# STM32F378xx register map
File version: 1.0
Registers are 32-bit, read-write, reset 0x0 unless marked. A register's access mark holds for its fields unless they carry their own. Offsets are from the block's base; [hi:lo] are bit positions.

## COMP12_COMMON
Base 0x4001001C; alternate view of COMP
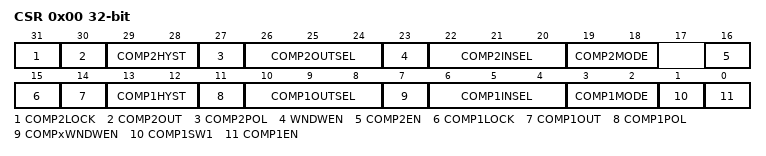
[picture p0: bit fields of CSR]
0x00 CSR — COMP control and status register, used for bits common to several COMP instances
  [31] COMP2LOCK
  [30] COMP2OUT — COMP2 output level
  [29:28] COMP2HYST — COMP2 hysteresis
  [27] COMP2POL — COMP2 output polarity
  [26:24] COMP2OUTSEL — COMP2 output select
  [23] WNDWEN — Comparators window mode enable
    0=DISABLE (Window mode disable: Comparators 1 and 2 are independent); 1=COMP1_INPUT_PLUS_COMMON (Window mode enable: Comparators instances pair COMP1 and COMP2 have their input plus connected together. The common input is COMP1 input plus (COMP2 input plus is no more accessible).)
  [22:20] COMP2INSEL — COMP2 inverting input select
  [19:18] COMP2MODE — COMP2 power mode
  [16] COMP2EN — COMP2 enable
  [15] COMP1LOCK
  [14] COMP1OUT — COMP1 output level
  [13:12] COMP1HYST — COMP1 hysteresis
    0=NONE (No hysteresis); 1=LOW (Hysteresis level low (available only on devices: STM32F303xB/C, STM32F358xC)); 2=MEDIUM (Hysteresis level medium (available only on devices: STM32F303xB/C, STM32F358xC)); 3=HIGH (Hysteresis level high (available only on devices: STM32F303xB/C, STM32F358xC))
  [11] COMP1POL — COMP1 output polarity
    0=NONINVERTED (COMP output polarity is not inverted: comparator output is high when the plus (non-inverting) input is at a higher voltage than the minus (inverting) input); 1=INVERTED (COMP output polarity is inverted: comparator output is low when the plus (non-inverting) input is at a lower voltage than the minus (inverting) input)
  [10:8] COMP1OUTSEL — COMP1 output select
    0=NONE (COMP output is not connected to other peripherals (except GPIO and EXTI that are always connected to COMP output) (specific to COMP instance: COMP2)); 1=TIM16_BKIN (COMP output connected to TIM16 break input (BKIN). Caution: Parameter specific to COMP instances, defined with generic naming, not taking into account COMP instance constraints. Refer to literal definitions above for COMP instance constraints.); 2=TIM4_IC1 (COMP output connected to TIM4 input capture 1. Caution: Parameter specific to COMP instances, defined with generic naming, not taking into account COMP instance constraints. Refer to literal definitions above for COMP instance constraints.); 3=TIM4_OCCLR (COMP output connected to TIM4 OCREF clear. Caution: Parameter specific to COMP instances, defined with generic naming, not taking into account COMP instance constraints. Refer to literal definitions above for COMP instance constraints.); 4=TIM2_IC4 (COMP output connected to TIM2 input capture 4. Caution: Parameter specific to COMP instances, defined with generic naming, not taking into account COMP instance constraints. Refer to literal definitions above for COMP instance constraints.); 5=TIM2_OCCLR (COMP output connected to TIM2 OCREF clear)
  [7] COMPxWNDWEN — COMPx window mode enable
  [6:4] COMP1INSEL — COMP1 inverting input select
    0=MINUS_1_4VREFINT (Comparator input minus connected to 1/4 VrefInt); 1=MINUS_1_2VREFINT (Comparator input minus connected to 1/2 VrefInt); 2=MINUS_3_4VREFINT (Comparator input minus connected to 3/4 VrefInt); 3=VREFINT (Comparator input minus connected to VrefInt); 4=DAC1_CH1 (Comparator input minus connected to DAC1 channel 1 (DAC_OUT1)); 5=DAC1_CH2 (Comparator input minus connected to DAC1 channel 2 (DAC_OUT2)); 6=IO1 (Comparator input minus connected to IO1 (pin PA2 for COMP2)); 7=IO2 (Comparator input minus connected to IO2 (PB12 for COMP3, PB2 for COMP4, PB10 for COMP5, PB15 for COMP6 (COMP instance availability depends on the selected device)))
  [3:2] COMP1MODE — COMP1 power mode
    0=HIGHSPEED (COMP power mode to high speed); 1=MEDIUMSPEED (COMP power mode to medium speed); 2=LOWPOWER (COMP power mode to low power); 3=ULTRALOWPOWER (COMP power mode to ultra-low power)
  [1] COMP1SW1 — SW1 switch control
    0=IO1 (Comparator input plus connected to IO1 (pin PA1 for COMP1, PA3 for COMP2 (except STM32F334xx: PA7), PB14 for COMP3, PB0 for COMP4, PD12 for COMP5, PD11 for COMP6, PA0 for COMP7) (COMP instance availability depends on the selected device)); 1=DAC1_CH1 (Comparator input plus connected to DAC1 channel 1 (DAC_OUT1), through dedicated switch. Caution: Parameter specific to COMP instances, defined with generic naming, not taking into account COMP instance constraints. Refer to literal definitions above for COMP instance constraints.)
  [0] COMP1EN — COMP1 enable
